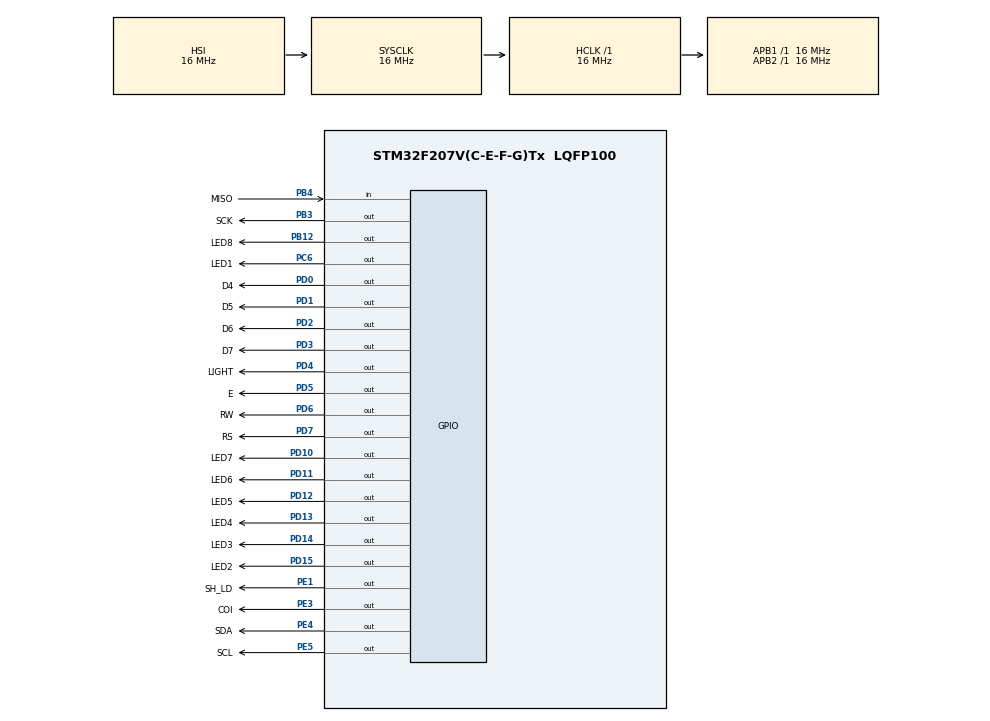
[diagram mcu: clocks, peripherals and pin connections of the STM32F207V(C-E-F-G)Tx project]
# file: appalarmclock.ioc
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Mcu.Family=STM32F2
Mcu.Name=STM32F207V(C-E-F-G)Tx
Mcu.Package=LQFP100
NVIC.PriorityGroup=NVIC_PRIORITYGROUP_4
NVIC.TIM1_UP_TIM10_IRQn=true\:0\:0\:false\:false\:true\:true\:true\:true
PA13.Mode=Serial_Wire
PA13.Signal=SYS_JTMS-SWDIO
PA14.Mode=Serial_Wire
PA14.Signal=SYS_JTCK-SWCLK
PB12.GPIO_Label=LED8
PB12.Signal=GPIO_Output
PB3.GPIO_Label=SCK
PB3.Signal=GPIO_Output
PB4.GPIO_Label=MISO
PB4.Signal=GPIO_Input
PC6.GPIO_Label=LED1
PC6.Signal=GPIO_Output
PD0.GPIO_Label=D4
PD0.Signal=GPIO_Output
PD1.GPIO_Label=D5
PD1.Signal=GPIO_Output
PD10.GPIO_Label=LED7
PD10.Signal=GPIO_Output
PD11.GPIO_Label=LED6
PD11.Signal=GPIO_Output
PD12.GPIO_Label=LED5
PD12.Signal=GPIO_Output
PD13.GPIO_Label=LED4
PD13.Signal=GPIO_Output
PD14.GPIO_Label=LED3
PD14.Signal=GPIO_Output
PD15.GPIO_Label=LED2
PD15.Signal=GPIO_Output
PD2.GPIO_Label=D6
PD2.Signal=GPIO_Output
PD3.GPIO_Label=D7
PD3.Signal=GPIO_Output
PD4.GPIO_Label=LIGHT
PD4.PinState=GPIO_PIN_SET
PD4.Signal=GPIO_Output
PD5.GPIO_Label=E
PD5.Signal=GPIO_Output
PD6.GPIO_Label=RW
PD6.Signal=GPIO_Output
PD7.GPIO_Label=RS
PD7.Signal=GPIO_Output
PE1.GPIO_Label=SH_LD
PE1.Signal=GPIO_Output
PE3.GPIO_Label=COI
PE3.PinState=GPIO_PIN_SET
PE3.Signal=GPIO_Output
PE4.GPIO_Label=SDA
PE4.GPIO_ModeDefaultOutputPP=GPIO_MODE_OUTPUT_OD
PE4.GPIO_PuPd=GPIO_PULLUP
PE4.PinState=GPIO_PIN_SET
PE4.Signal=GPIO_Output
PE5.GPIO_Label=SCL
PE5.GPIO_ModeDefaultOutputPP=GPIO_MODE_OUTPUT_OD
PE5.GPIO_PuPd=GPIO_PULLUP
PE5.PinState=GPIO_PIN_SET
PE5.Signal=GPIO_Output
ProjectManager.HeapSize=0x200
ProjectManager.StackSize=0x400
ProjectManager.TargetToolchain=STM32CubeIDE
RCC.48MHZClocksFreq_Value=48000000
RCC.AHBFreq_Value=16000000
RCC.APB1Freq_Value=16000000
RCC.APB2Freq_Value=16000000
RCC.CortexFreq_Value=16000000
RCC.HSE_VALUE=25000000
RCC.HSI_VALUE=16000000
RCC.LSE_VALUE=32768
RCC.SYSCLKFreq_VALUE=16000000
RCC.VCOOutputFreq_Value=192000000
TIM1.Period=0xFFFF
TIM1.Prescaler=15999
VP_TIM1_VS_ClockSourceINT.Mode=Internal
board=custom

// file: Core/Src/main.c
/* USER CODE BEGIN Header */
/**
  ******************************************************************************
  * @file           : main.c
  * @brief          : Main program body
  ******************************************************************************
  * @attention
  *
  * Copyright (c) 2026 STMicroelectronics.
  * All rights reserved.
  *
  * This software is licensed under terms that can be found in the LICENSE file
  * in the root directory of this software component.
  * If no LICENSE file comes with this software, it is provided AS-IS.
  *
  ******************************************************************************
  */
/* USER CODE END Header */
#include "main.h"

/* USER CODE BEGIN Includes */
#include "app_clock.h"
#include "lcd.h"
#include "clock.h"
#include "menu.h"
#include "button_event.h"
#include "ui.h"
#include "timer.h"
#include "buzzer.h"
/* USER CODE END Includes */

TIM_HandleTypeDef htim1;

void SystemClock_Config(void);
static void MX_GPIO_Init(void);
static void MX_TIM1_Init(void);

int main(void)
{

  /* MCU Configuration--------------------------------------------------------*/

  /* Reset of all peripherals, Initializes the Flash interface and the Systick. */
  HAL_Init();

  /* Configure the system clock */
  SystemClock_Config();

  /* Initialize all configured peripherals */
  MX_GPIO_Init();
  MX_TIM1_Init();
  /* USER CODE BEGIN 2 */
  lcd_init();
  app_clock_init();
  buzzer_off();
  /* USER CODE END 2 */

  /* Infinite loop */
  /* USER CODE BEGIN WHILE */
  while (1)
  {
	    app_clock_process();

    /* USER CODE END WHILE */

  }
}

void SystemClock_Config(void)
{
  RCC_OscInitTypeDef RCC_OscInitStruct = {0};
  RCC_ClkInitTypeDef RCC_ClkInitStruct = {0};

  /** Initializes the RCC Oscillators according to the specified parameters
  * in the RCC_OscInitTypeDef structure.
  */
  RCC_OscInitStruct.OscillatorType = RCC_OSCILLATORTYPE_HSI;
  RCC_OscInitStruct.HSIState = RCC_HSI_ON;
  RCC_OscInitStruct.HSICalibrationValue = RCC_HSICALIBRATION_DEFAULT;
  RCC_OscInitStruct.PLL.PLLState = RCC_PLL_NONE;
  if (HAL_RCC_OscConfig(&RCC_OscInitStruct) != HAL_OK)
  {
    Error_Handler();
  }

  /** Initializes the CPU, AHB and APB buses clocks
  */
  RCC_ClkInitStruct.ClockType = RCC_CLOCKTYPE_HCLK|RCC_CLOCKTYPE_SYSCLK
                              |RCC_CLOCKTYPE_PCLK1|RCC_CLOCKTYPE_PCLK2;
  RCC_ClkInitStruct.SYSCLKSource = RCC_SYSCLKSOURCE_HSI;
  RCC_ClkInitStruct.AHBCLKDivider = RCC_SYSCLK_DIV1;
  RCC_ClkInitStruct.APB1CLKDivider = RCC_HCLK_DIV1;
  RCC_ClkInitStruct.APB2CLKDivider = RCC_HCLK_DIV1;

  if (HAL_RCC_ClockConfig(&RCC_ClkInitStruct, FLASH_LATENCY_0) != HAL_OK)
  {
    Error_Handler();
  }
}

static void MX_TIM1_Init(void)
{

  TIM_ClockConfigTypeDef sClockSourceConfig = {0};
  TIM_MasterConfigTypeDef sMasterConfig = {0};

  htim1.Instance = TIM1;
  htim1.Init.Prescaler = 15999;
  htim1.Init.CounterMode = TIM_COUNTERMODE_UP;
  htim1.Init.Period = 0xFFFF;
  htim1.Init.ClockDivision = TIM_CLOCKDIVISION_DIV1;
  htim1.Init.RepetitionCounter = 0;
  htim1.Init.AutoReloadPreload = TIM_AUTORELOAD_PRELOAD_DISABLE;
  if (HAL_TIM_Base_Init(&htim1) != HAL_OK)
  {
    Error_Handler();
  }
  sClockSourceConfig.ClockSource = TIM_CLOCKSOURCE_INTERNAL;
  if (HAL_TIM_ConfigClockSource(&htim1, &sClockSourceConfig) != HAL_OK)
  {
    Error_Handler();
  }
  sMasterConfig.MasterOutputTrigger = TIM_TRGO_RESET;
  sMasterConfig.MasterSlaveMode = TIM_MASTERSLAVEMODE_DISABLE;
  if (HAL_TIMEx_MasterConfigSynchronization(&htim1, &sMasterConfig) != HAL_OK)
  {
    Error_Handler();
  }

}

static void MX_GPIO_Init(void)
{
  GPIO_InitTypeDef GPIO_InitStruct = {0};

  /* GPIO Ports Clock Enable */
  __HAL_RCC_GPIOE_CLK_ENABLE();
  __HAL_RCC_GPIOB_CLK_ENABLE();
  __HAL_RCC_GPIOD_CLK_ENABLE();
  __HAL_RCC_GPIOC_CLK_ENABLE();
  __HAL_RCC_GPIOA_CLK_ENABLE();

  /*Configure GPIO pin Output Level */
  HAL_GPIO_WritePin(GPIOE, COI_Pin|SDA_Pin|SCL_Pin, GPIO_PIN_SET);

  /*Configure GPIO pin Output Level */
  HAL_GPIO_WritePin(GPIOB, LED8_Pin|SCK_Pin, GPIO_PIN_RESET);

  /*Configure GPIO pin Output Level */
  HAL_GPIO_WritePin(GPIOD, LED7_Pin|LED6_Pin|LED5_Pin|LED4_Pin
                          |LED3_Pin|LED2_Pin|D4_Pin|D5_Pin
                          |D6_Pin|D7_Pin|E_Pin|RW_Pin
                          |RS_Pin, GPIO_PIN_RESET);

  /*Configure GPIO pin Output Level */
  HAL_GPIO_WritePin(LED1_GPIO_Port, LED1_Pin, GPIO_PIN_RESET);

  /*Configure GPIO pin Output Level */
  HAL_GPIO_WritePin(LIGHT_GPIO_Port, LIGHT_Pin, GPIO_PIN_SET);

  /*Configure GPIO pin Output Level */
  HAL_GPIO_WritePin(SH_LD_GPIO_Port, SH_LD_Pin, GPIO_PIN_RESET);

  /*Configure GPIO pins : COI_Pin SH_LD_Pin */
  GPIO_InitStruct.Pin = COI_Pin|SH_LD_Pin;
  GPIO_InitStruct.Mode = GPIO_MODE_OUTPUT_PP;
  GPIO_InitStruct.Pull = GPIO_NOPULL;
  GPIO_InitStruct.Speed = GPIO_SPEED_FREQ_LOW;
  HAL_GPIO_Init(GPIOE, &GPIO_InitStruct);

  /*Configure GPIO pins : SDA_Pin SCL_Pin */
  GPIO_InitStruct.Pin = SDA_Pin|SCL_Pin;
  GPIO_InitStruct.Mode = GPIO_MODE_OUTPUT_OD;
  GPIO_InitStruct.Pull = GPIO_PULLUP;
  GPIO_InitStruct.Speed = GPIO_SPEED_FREQ_LOW;
  HAL_GPIO_Init(GPIOE, &GPIO_InitStruct);

  /*Configure GPIO pins : LED8_Pin SCK_Pin */
  GPIO_InitStruct.Pin = LED8_Pin|SCK_Pin;
  GPIO_InitStruct.Mode = GPIO_MODE_OUTPUT_PP;
  GPIO_InitStruct.Pull = GPIO_NOPULL;
  GPIO_InitStruct.Speed = GPIO_SPEED_FREQ_LOW;
  HAL_GPIO_Init(GPIOB, &GPIO_InitStruct);

  /*Configure GPIO pins : LED7_Pin LED6_Pin LED5_Pin LED4_Pin
                           LED3_Pin LED2_Pin D4_Pin D5_Pin
                           D6_Pin D7_Pin LIGHT_Pin E_Pin
                           RW_Pin RS_Pin */
  GPIO_InitStruct.Pin = LED7_Pin|LED6_Pin|LED5_Pin|LED4_Pin
                          |LED3_Pin|LED2_Pin|D4_Pin|D5_Pin
                          |D6_Pin|D7_Pin|LIGHT_Pin|E_Pin
                          |RW_Pin|RS_Pin;
  GPIO_InitStruct.Mode = GPIO_MODE_OUTPUT_PP;
  GPIO_InitStruct.Pull = GPIO_NOPULL;
  GPIO_InitStruct.Speed = GPIO_SPEED_FREQ_LOW;
  HAL_GPIO_Init(GPIOD, &GPIO_InitStruct);

  /*Configure GPIO pin : LED1_Pin */
  GPIO_InitStruct.Pin = LED1_Pin;
  GPIO_InitStruct.Mode = GPIO_MODE_OUTPUT_PP;
  GPIO_InitStruct.Pull = GPIO_NOPULL;
  GPIO_InitStruct.Speed = GPIO_SPEED_FREQ_LOW;
  HAL_GPIO_Init(LED1_GPIO_Port, &GPIO_InitStruct);

  /*Configure GPIO pin : MISO_Pin */
  GPIO_InitStruct.Pin = MISO_Pin;
  GPIO_InitStruct.Mode = GPIO_MODE_INPUT;
  GPIO_InitStruct.Pull = GPIO_NOPULL;
  HAL_GPIO_Init(MISO_GPIO_Port, &GPIO_InitStruct);

}

void Error_Handler(void)
{
  __disable_irq();
  while (1)
  {
  }
}
